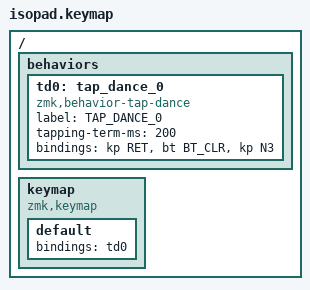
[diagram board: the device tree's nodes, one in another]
/*
 * Copyright (c) 2021 Dan Thomas
 *
 * SPDX-License-Identifier: MIT
 */

#include <behaviors.dtsi>
#include <dt-bindings/zmk/keys.h>
#include <dt-bindings/zmk/bt.h>

/ {
    behaviors {
        td0: tap_dance_0 {
            compatible = "zmk,behavior-tap-dance";
            label = "TAP_DANCE_0";
            #binding-cells = <0>;
            tapping-term-ms = <200>;
            bindings = <&kp RET>, <&bt BT_CLR>, <&kp N3>;
        };
    };

    keymap {
        compatible = "zmk,keymap";

        default {
           bindings = <
// You probably want to change the line below...
                &td0
            >;
        };
	};
};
